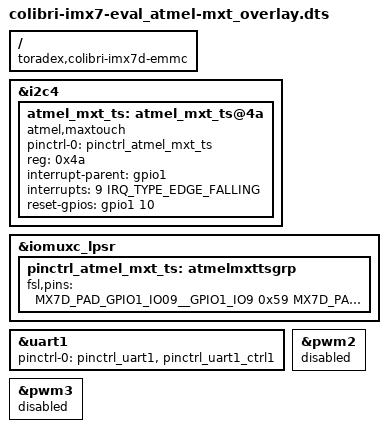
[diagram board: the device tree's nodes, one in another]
// Atmel touchscreen for the 7inch capacitive display orderable at Toradex. Use this devicetree on the Evaluation or Iris board.

/dts-v1/;
/plugin/;

#include <dt-bindings/gpio/gpio.h>
#include <dt-bindings/interrupt-controller/irq.h>
#include <imx7d-pinfunc.h>

/ {
	compatible = "toradex,colibri-imx7d-emmc";
};

&i2c4 {
	#address-cells = <1>;
	#size-cells = <0>;

	atmel_mxt_ts: atmel_mxt_ts@4a {
		pinctrl-names = "default";
		pinctrl-0 = <&pinctrl_atmel_mxt_ts>;
		compatible = "atmel,maxtouch";
		reg = <0x4a>;
		interrupt-parent = <&gpio1>;
		interrupts = <9 IRQ_TYPE_EDGE_FALLING>;
		reset-gpios = <&gpio1 10 GPIO_ACTIVE_HIGH>;
		status = "okay";
	};
};

&iomuxc_lpsr  {
	pinctrl_atmel_mxt_ts: atmelmxttsgrp {
		fsl,pins = <
			MX7D_PAD_GPIO1_IO09__GPIO1_IO9	0x59
			MX7D_PAD_GPIO1_IO10__GPIO1_IO10	0x59
		>;
	};
};

&uart1 {
	pinctrl-0 = <&pinctrl_uart1 &pinctrl_uart1_ctrl1>;
};

&pwm2 {
	status = "disabled";
};

&pwm3 {
	status = "disabled";
};
